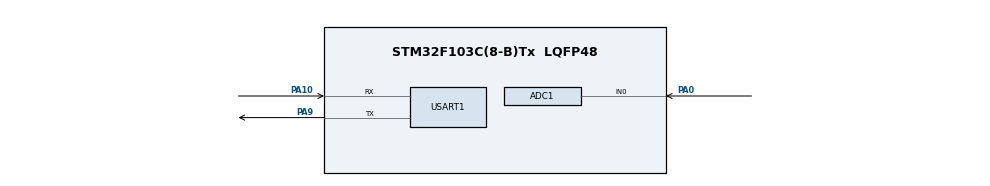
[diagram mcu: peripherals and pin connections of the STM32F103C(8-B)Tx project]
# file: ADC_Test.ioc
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ADC1.Channel-0\#ChannelRegularConversion=ADC_CHANNEL_0
ADC1.NbrOfConversionFlag=1
ADC1.Rank-0\#ChannelRegularConversion=1
ADC1.SamplingTime-0\#ChannelRegularConversion=ADC_SAMPLETIME_1CYCLE_5
ADC1.master=1
Mcu.Family=STM32F1
Mcu.Name=STM32F103C(8-B)Tx
Mcu.Package=LQFP48
NVIC.PriorityGroup=NVIC_PRIORITYGROUP_4
NVIC.USART1_IRQn=true\:0\:0\:false\:false\:true\:true\:true
PA0-WKUP.Signal=ADCx_IN0
PA10.Mode=Asynchronous
PA10.Signal=USART1_RX
PA9.Mode=Asynchronous
PA9.Signal=USART1_TX
ProjectManager.HeapSize=0x200
ProjectManager.StackSize=0x400
ProjectManager.TargetToolchain=MDK-ARM V5.27
RCC.APB1Freq_Value=8000000
RCC.APB2Freq_Value=8000000
SH.ADCx_IN0.0=ADC1_IN0,IN0
USART1.VirtualMode=VM_ASYNC
VP_SYS_VS_ND.Mode=No_Debug
board=custom

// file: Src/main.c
/* USER CODE BEGIN Header */
/**
  ******************************************************************************
  * @file           : main.c
  * @brief          : Main program body
  ******************************************************************************
  * @attention
  *
  * <h2><center>&copy; Copyright (c) 2020 STMicroelectronics.
  * All rights reserved.</center></h2>
  *
  * This software component is licensed by ST under BSD 3-Clause license,
  * the "License"; You may not use this file except in compliance with the
  * License. You may obtain a copy of the License at:
  *                        opensource.org/licenses/BSD-3-Clause
  *
  ******************************************************************************
  */
/* USER CODE END Header */

#include "main.h"
#include "adc.h"
#include "usart.h"
#include "gpio.h"

/* USER CODE BEGIN Includes */
#include "stdio.h"
/* USER CODE END Includes */

/* USER CODE BEGIN PM */
int fputc(int ch,FILE *f);
int fgetc(FILE *f);
/* USER CODE END PM */

/* USER CODE BEGIN PV */
uint8_t ch_r;
/* USER CODE END PV */

void SystemClock_Config(void);

int main(void)
{
  /* USER CODE BEGIN 1 */
	uint32_t AD_Value=0;
	uint16_t count=0;
  /* USER CODE END 1 */

  /* MCU Configuration--------------------------------------------------------*/

  /* Reset of all peripherals, Initializes the Flash interface and the Systick. */
  HAL_Init();

  /* Configure the system clock */
  SystemClock_Config();

  /* Initialize all configured peripherals */
  MX_GPIO_Init();
  MX_ADC1_Init();
  MX_USART1_UART_Init();

  /* Infinite loop */
  /* USER CODE BEGIN WHILE */
  while (1)
  {
		HAL_ADC_Start(&hadc1);
		HAL_ADC_PollForConversion(&hadc1, 100);
		AD_Value = HAL_ADC_GetValue(&hadc1);
		count++;
		if(count == 60000){
			printf("get Value:%f\r\n",(float)AD_Value*(5.0/1023.0));
			count=0;
		}
    /* USER CODE END WHILE */

  }
}

void SystemClock_Config(void)
{
  RCC_OscInitTypeDef RCC_OscInitStruct = {0};
  RCC_ClkInitTypeDef RCC_ClkInitStruct = {0};
  RCC_PeriphCLKInitTypeDef PeriphClkInit = {0};

  /** Initializes the CPU, AHB and APB busses clocks
  */
  RCC_OscInitStruct.OscillatorType = RCC_OSCILLATORTYPE_HSI;
  RCC_OscInitStruct.HSIState = RCC_HSI_ON;
  RCC_OscInitStruct.HSICalibrationValue = RCC_HSICALIBRATION_DEFAULT;
  RCC_OscInitStruct.PLL.PLLState = RCC_PLL_NONE;
  if (HAL_RCC_OscConfig(&RCC_OscInitStruct) != HAL_OK)
  {
    Error_Handler();
  }
  /** Initializes the CPU, AHB and APB busses clocks
  */
  RCC_ClkInitStruct.ClockType = RCC_CLOCKTYPE_HCLK|RCC_CLOCKTYPE_SYSCLK
                              |RCC_CLOCKTYPE_PCLK1|RCC_CLOCKTYPE_PCLK2;
  RCC_ClkInitStruct.SYSCLKSource = RCC_SYSCLKSOURCE_HSI;
  RCC_ClkInitStruct.AHBCLKDivider = RCC_SYSCLK_DIV1;
  RCC_ClkInitStruct.APB1CLKDivider = RCC_HCLK_DIV1;
  RCC_ClkInitStruct.APB2CLKDivider = RCC_HCLK_DIV1;

  if (HAL_RCC_ClockConfig(&RCC_ClkInitStruct, FLASH_LATENCY_0) != HAL_OK)
  {
    Error_Handler();
  }
  PeriphClkInit.PeriphClockSelection = RCC_PERIPHCLK_ADC;
  PeriphClkInit.AdcClockSelection = RCC_ADCPCLK2_DIV2;
  if (HAL_RCCEx_PeriphCLKConfig(&PeriphClkInit) != HAL_OK)
  {
    Error_Handler();
  }
}

/* USER CODE BEGIN 4 */
int fputc(int ch,FILE *f)
{
    uint32_t temp = ch;

    HAL_UART_Transmit(&huart1,(uint8_t *)&temp,1,1000);
    return ch;
}
int fgetc(FILE * F)
{

	HAL_UART_Receive (&huart1,&ch_r,1,0xffff);
	return ch_r;
}
/* USER CODE END 4 */

void Error_Handler(void)
{
}

/************************ (C) COPYRIGHT STMicroelectronics *****END OF FILE****/
